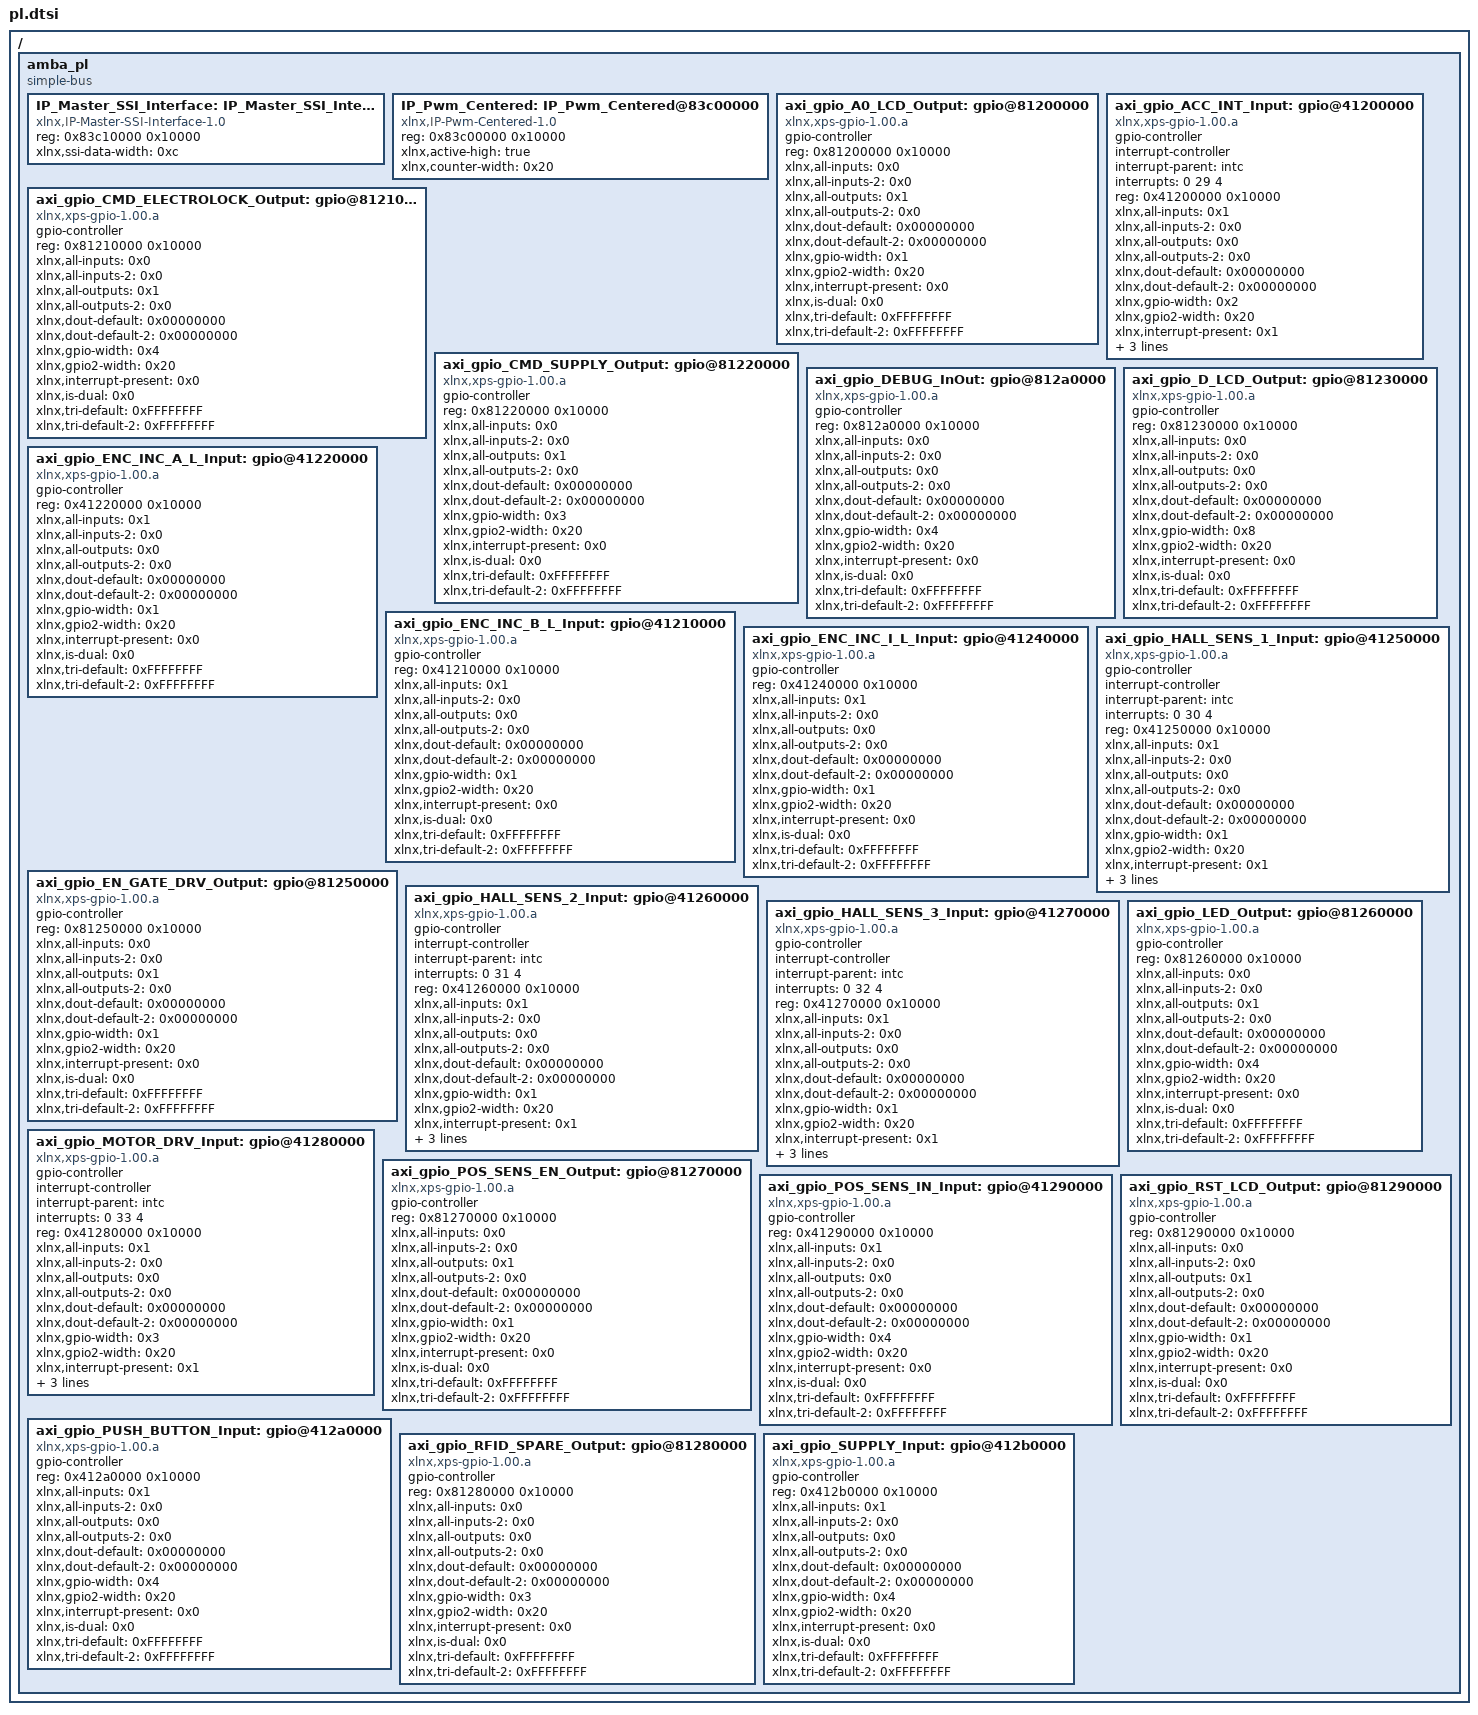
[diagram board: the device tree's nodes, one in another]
/*
 * CAUTION: This file is automatically generated by Xilinx.
 * Version:  
 * Today is: Fri May 19 15:57:43 2017
*/


/ {
	amba_pl: amba_pl {
		#address-cells = <1>;
		#size-cells = <1>;
		compatible = "simple-bus";
		ranges ;
		IP_Master_SSI_Interface: IP_Master_SSI_Interface@83c10000 {
			compatible = "xlnx,IP-Master-SSI-Interface-1.0";
			reg = <0x83c10000 0x10000>;
			xlnx,ssi-data-width = <0xc>;
		};
		IP_Pwm_Centered: IP_Pwm_Centered@83c00000 {
			compatible = "xlnx,IP-Pwm-Centered-1.0";
			reg = <0x83c00000 0x10000>;
			xlnx,active-high = "true";
			xlnx,counter-width = <0x20>;
		};
		axi_gpio_A0_LCD_Output: gpio@81200000 {
			#gpio-cells = <2>;
			compatible = "xlnx,xps-gpio-1.00.a";
			gpio-controller ;
			reg = <0x81200000 0x10000>;
			xlnx,all-inputs = <0x0>;
			xlnx,all-inputs-2 = <0x0>;
			xlnx,all-outputs = <0x1>;
			xlnx,all-outputs-2 = <0x0>;
			xlnx,dout-default = <0x00000000>;
			xlnx,dout-default-2 = <0x00000000>;
			xlnx,gpio-width = <0x1>;
			xlnx,gpio2-width = <0x20>;
			xlnx,interrupt-present = <0x0>;
			xlnx,is-dual = <0x0>;
			xlnx,tri-default = <0xFFFFFFFF>;
			xlnx,tri-default-2 = <0xFFFFFFFF>;
		};
		axi_gpio_ACC_INT_Input: gpio@41200000 {
			#gpio-cells = <2>;
			#interrupt-cells = <2>;
			compatible = "xlnx,xps-gpio-1.00.a";
			gpio-controller ;
			interrupt-controller ;
			interrupt-parent = <&intc>;
			interrupts = <0 29 4>;
			reg = <0x41200000 0x10000>;
			xlnx,all-inputs = <0x1>;
			xlnx,all-inputs-2 = <0x0>;
			xlnx,all-outputs = <0x0>;
			xlnx,all-outputs-2 = <0x0>;
			xlnx,dout-default = <0x00000000>;
			xlnx,dout-default-2 = <0x00000000>;
			xlnx,gpio-width = <0x2>;
			xlnx,gpio2-width = <0x20>;
			xlnx,interrupt-present = <0x1>;
			xlnx,is-dual = <0x0>;
			xlnx,tri-default = <0xFFFFFFFF>;
			xlnx,tri-default-2 = <0xFFFFFFFF>;
		};
		axi_gpio_CMD_ELECTROLOCK_Output: gpio@81210000 {
			#gpio-cells = <2>;
			compatible = "xlnx,xps-gpio-1.00.a";
			gpio-controller ;
			reg = <0x81210000 0x10000>;
			xlnx,all-inputs = <0x0>;
			xlnx,all-inputs-2 = <0x0>;
			xlnx,all-outputs = <0x1>;
			xlnx,all-outputs-2 = <0x0>;
			xlnx,dout-default = <0x00000000>;
			xlnx,dout-default-2 = <0x00000000>;
			xlnx,gpio-width = <0x4>;
			xlnx,gpio2-width = <0x20>;
			xlnx,interrupt-present = <0x0>;
			xlnx,is-dual = <0x0>;
			xlnx,tri-default = <0xFFFFFFFF>;
			xlnx,tri-default-2 = <0xFFFFFFFF>;
		};
		axi_gpio_CMD_SUPPLY_Output: gpio@81220000 {
			#gpio-cells = <2>;
			compatible = "xlnx,xps-gpio-1.00.a";
			gpio-controller ;
			reg = <0x81220000 0x10000>;
			xlnx,all-inputs = <0x0>;
			xlnx,all-inputs-2 = <0x0>;
			xlnx,all-outputs = <0x1>;
			xlnx,all-outputs-2 = <0x0>;
			xlnx,dout-default = <0x00000000>;
			xlnx,dout-default-2 = <0x00000000>;
			xlnx,gpio-width = <0x3>;
			xlnx,gpio2-width = <0x20>;
			xlnx,interrupt-present = <0x0>;
			xlnx,is-dual = <0x0>;
			xlnx,tri-default = <0xFFFFFFFF>;
			xlnx,tri-default-2 = <0xFFFFFFFF>;
		};
		axi_gpio_DEBUG_InOut: gpio@812a0000 {
			#gpio-cells = <2>;
			compatible = "xlnx,xps-gpio-1.00.a";
			gpio-controller ;
			reg = <0x812a0000 0x10000>;
			xlnx,all-inputs = <0x0>;
			xlnx,all-inputs-2 = <0x0>;
			xlnx,all-outputs = <0x0>;
			xlnx,all-outputs-2 = <0x0>;
			xlnx,dout-default = <0x00000000>;
			xlnx,dout-default-2 = <0x00000000>;
			xlnx,gpio-width = <0x4>;
			xlnx,gpio2-width = <0x20>;
			xlnx,interrupt-present = <0x0>;
			xlnx,is-dual = <0x0>;
			xlnx,tri-default = <0xFFFFFFFF>;
			xlnx,tri-default-2 = <0xFFFFFFFF>;
		};
		axi_gpio_D_LCD_Output: gpio@81230000 {
			#gpio-cells = <2>;
			compatible = "xlnx,xps-gpio-1.00.a";
			gpio-controller ;
			reg = <0x81230000 0x10000>;
			xlnx,all-inputs = <0x0>;
			xlnx,all-inputs-2 = <0x0>;
			xlnx,all-outputs = <0x0>;
			xlnx,all-outputs-2 = <0x0>;
			xlnx,dout-default = <0x00000000>;
			xlnx,dout-default-2 = <0x00000000>;
			xlnx,gpio-width = <0x8>;
			xlnx,gpio2-width = <0x20>;
			xlnx,interrupt-present = <0x0>;
			xlnx,is-dual = <0x0>;
			xlnx,tri-default = <0xFFFFFFFF>;
			xlnx,tri-default-2 = <0xFFFFFFFF>;
		};
		axi_gpio_ENC_INC_A_L_Input: gpio@41220000 {
			#gpio-cells = <2>;
			compatible = "xlnx,xps-gpio-1.00.a";
			gpio-controller ;
			reg = <0x41220000 0x10000>;
			xlnx,all-inputs = <0x1>;
			xlnx,all-inputs-2 = <0x0>;
			xlnx,all-outputs = <0x0>;
			xlnx,all-outputs-2 = <0x0>;
			xlnx,dout-default = <0x00000000>;
			xlnx,dout-default-2 = <0x00000000>;
			xlnx,gpio-width = <0x1>;
			xlnx,gpio2-width = <0x20>;
			xlnx,interrupt-present = <0x0>;
			xlnx,is-dual = <0x0>;
			xlnx,tri-default = <0xFFFFFFFF>;
			xlnx,tri-default-2 = <0xFFFFFFFF>;
		};
		axi_gpio_ENC_INC_B_L_Input: gpio@41210000 {
			#gpio-cells = <2>;
			compatible = "xlnx,xps-gpio-1.00.a";
			gpio-controller ;
			reg = <0x41210000 0x10000>;
			xlnx,all-inputs = <0x1>;
			xlnx,all-inputs-2 = <0x0>;
			xlnx,all-outputs = <0x0>;
			xlnx,all-outputs-2 = <0x0>;
			xlnx,dout-default = <0x00000000>;
			xlnx,dout-default-2 = <0x00000000>;
			xlnx,gpio-width = <0x1>;
			xlnx,gpio2-width = <0x20>;
			xlnx,interrupt-present = <0x0>;
			xlnx,is-dual = <0x0>;
			xlnx,tri-default = <0xFFFFFFFF>;
			xlnx,tri-default-2 = <0xFFFFFFFF>;
		};
		axi_gpio_ENC_INC_I_L_Input: gpio@41240000 {
			#gpio-cells = <2>;
			compatible = "xlnx,xps-gpio-1.00.a";
			gpio-controller ;
			reg = <0x41240000 0x10000>;
			xlnx,all-inputs = <0x1>;
			xlnx,all-inputs-2 = <0x0>;
			xlnx,all-outputs = <0x0>;
			xlnx,all-outputs-2 = <0x0>;
			xlnx,dout-default = <0x00000000>;
			xlnx,dout-default-2 = <0x00000000>;
			xlnx,gpio-width = <0x1>;
			xlnx,gpio2-width = <0x20>;
			xlnx,interrupt-present = <0x0>;
			xlnx,is-dual = <0x0>;
			xlnx,tri-default = <0xFFFFFFFF>;
			xlnx,tri-default-2 = <0xFFFFFFFF>;
		};
		axi_gpio_EN_GATE_DRV_Output: gpio@81250000 {
			#gpio-cells = <2>;
			compatible = "xlnx,xps-gpio-1.00.a";
			gpio-controller ;
			reg = <0x81250000 0x10000>;
			xlnx,all-inputs = <0x0>;
			xlnx,all-inputs-2 = <0x0>;
			xlnx,all-outputs = <0x1>;
			xlnx,all-outputs-2 = <0x0>;
			xlnx,dout-default = <0x00000000>;
			xlnx,dout-default-2 = <0x00000000>;
			xlnx,gpio-width = <0x1>;
			xlnx,gpio2-width = <0x20>;
			xlnx,interrupt-present = <0x0>;
			xlnx,is-dual = <0x0>;
			xlnx,tri-default = <0xFFFFFFFF>;
			xlnx,tri-default-2 = <0xFFFFFFFF>;
		};
		axi_gpio_HALL_SENS_1_Input: gpio@41250000 {
			#gpio-cells = <2>;
			#interrupt-cells = <2>;
			compatible = "xlnx,xps-gpio-1.00.a";
			gpio-controller ;
			interrupt-controller ;
			interrupt-parent = <&intc>;
			interrupts = <0 30 4>;
			reg = <0x41250000 0x10000>;
			xlnx,all-inputs = <0x1>;
			xlnx,all-inputs-2 = <0x0>;
			xlnx,all-outputs = <0x0>;
			xlnx,all-outputs-2 = <0x0>;
			xlnx,dout-default = <0x00000000>;
			xlnx,dout-default-2 = <0x00000000>;
			xlnx,gpio-width = <0x1>;
			xlnx,gpio2-width = <0x20>;
			xlnx,interrupt-present = <0x1>;
			xlnx,is-dual = <0x0>;
			xlnx,tri-default = <0xFFFFFFFF>;
			xlnx,tri-default-2 = <0xFFFFFFFF>;
		};
		axi_gpio_HALL_SENS_2_Input: gpio@41260000 {
			#gpio-cells = <2>;
			#interrupt-cells = <2>;
			compatible = "xlnx,xps-gpio-1.00.a";
			gpio-controller ;
			interrupt-controller ;
			interrupt-parent = <&intc>;
			interrupts = <0 31 4>;
			reg = <0x41260000 0x10000>;
			xlnx,all-inputs = <0x1>;
			xlnx,all-inputs-2 = <0x0>;
			xlnx,all-outputs = <0x0>;
			xlnx,all-outputs-2 = <0x0>;
			xlnx,dout-default = <0x00000000>;
			xlnx,dout-default-2 = <0x00000000>;
			xlnx,gpio-width = <0x1>;
			xlnx,gpio2-width = <0x20>;
			xlnx,interrupt-present = <0x1>;
			xlnx,is-dual = <0x0>;
			xlnx,tri-default = <0xFFFFFFFF>;
			xlnx,tri-default-2 = <0xFFFFFFFF>;
		};
		axi_gpio_HALL_SENS_3_Input: gpio@41270000 {
			#gpio-cells = <2>;
			#interrupt-cells = <2>;
			compatible = "xlnx,xps-gpio-1.00.a";
			gpio-controller ;
			interrupt-controller ;
			interrupt-parent = <&intc>;
			interrupts = <0 32 4>;
			reg = <0x41270000 0x10000>;
			xlnx,all-inputs = <0x1>;
			xlnx,all-inputs-2 = <0x0>;
			xlnx,all-outputs = <0x0>;
			xlnx,all-outputs-2 = <0x0>;
			xlnx,dout-default = <0x00000000>;
			xlnx,dout-default-2 = <0x00000000>;
			xlnx,gpio-width = <0x1>;
			xlnx,gpio2-width = <0x20>;
			xlnx,interrupt-present = <0x1>;
			xlnx,is-dual = <0x0>;
			xlnx,tri-default = <0xFFFFFFFF>;
			xlnx,tri-default-2 = <0xFFFFFFFF>;
		};
		axi_gpio_LED_Output: gpio@81260000 {
			#gpio-cells = <2>;
			compatible = "xlnx,xps-gpio-1.00.a";
			gpio-controller ;
			reg = <0x81260000 0x10000>;
			xlnx,all-inputs = <0x0>;
			xlnx,all-inputs-2 = <0x0>;
			xlnx,all-outputs = <0x1>;
			xlnx,all-outputs-2 = <0x0>;
			xlnx,dout-default = <0x00000000>;
			xlnx,dout-default-2 = <0x00000000>;
			xlnx,gpio-width = <0x4>;
			xlnx,gpio2-width = <0x20>;
			xlnx,interrupt-present = <0x0>;
			xlnx,is-dual = <0x0>;
			xlnx,tri-default = <0xFFFFFFFF>;
			xlnx,tri-default-2 = <0xFFFFFFFF>;
		};
		axi_gpio_MOTOR_DRV_Input: gpio@41280000 {
			#gpio-cells = <2>;
			#interrupt-cells = <2>;
			compatible = "xlnx,xps-gpio-1.00.a";
			gpio-controller ;
			interrupt-controller ;
			interrupt-parent = <&intc>;
			interrupts = <0 33 4>;
			reg = <0x41280000 0x10000>;
			xlnx,all-inputs = <0x1>;
			xlnx,all-inputs-2 = <0x0>;
			xlnx,all-outputs = <0x0>;
			xlnx,all-outputs-2 = <0x0>;
			xlnx,dout-default = <0x00000000>;
			xlnx,dout-default-2 = <0x00000000>;
			xlnx,gpio-width = <0x3>;
			xlnx,gpio2-width = <0x20>;
			xlnx,interrupt-present = <0x1>;
			xlnx,is-dual = <0x0>;
			xlnx,tri-default = <0xFFFFFFFF>;
			xlnx,tri-default-2 = <0xFFFFFFFF>;
		};
		axi_gpio_POS_SENS_EN_Output: gpio@81270000 {
			#gpio-cells = <2>;
			compatible = "xlnx,xps-gpio-1.00.a";
			gpio-controller ;
			reg = <0x81270000 0x10000>;
			xlnx,all-inputs = <0x0>;
			xlnx,all-inputs-2 = <0x0>;
			xlnx,all-outputs = <0x1>;
			xlnx,all-outputs-2 = <0x0>;
			xlnx,dout-default = <0x00000000>;
			xlnx,dout-default-2 = <0x00000000>;
			xlnx,gpio-width = <0x1>;
			xlnx,gpio2-width = <0x20>;
			xlnx,interrupt-present = <0x0>;
			xlnx,is-dual = <0x0>;
			xlnx,tri-default = <0xFFFFFFFF>;
			xlnx,tri-default-2 = <0xFFFFFFFF>;
		};
		axi_gpio_POS_SENS_IN_Input: gpio@41290000 {
			#gpio-cells = <2>;
			compatible = "xlnx,xps-gpio-1.00.a";
			gpio-controller ;
			reg = <0x41290000 0x10000>;
			xlnx,all-inputs = <0x1>;
			xlnx,all-inputs-2 = <0x0>;
			xlnx,all-outputs = <0x0>;
			xlnx,all-outputs-2 = <0x0>;
			xlnx,dout-default = <0x00000000>;
			xlnx,dout-default-2 = <0x00000000>;
			xlnx,gpio-width = <0x4>;
			xlnx,gpio2-width = <0x20>;
			xlnx,interrupt-present = <0x0>;
			xlnx,is-dual = <0x0>;
			xlnx,tri-default = <0xFFFFFFFF>;
			xlnx,tri-default-2 = <0xFFFFFFFF>;
		};
		axi_gpio_PUSH_BUTTON_Input: gpio@412a0000 {
			#gpio-cells = <2>;
			compatible = "xlnx,xps-gpio-1.00.a";
			gpio-controller ;
			reg = <0x412a0000 0x10000>;
			xlnx,all-inputs = <0x1>;
			xlnx,all-inputs-2 = <0x0>;
			xlnx,all-outputs = <0x0>;
			xlnx,all-outputs-2 = <0x0>;
			xlnx,dout-default = <0x00000000>;
			xlnx,dout-default-2 = <0x00000000>;
			xlnx,gpio-width = <0x4>;
			xlnx,gpio2-width = <0x20>;
			xlnx,interrupt-present = <0x0>;
			xlnx,is-dual = <0x0>;
			xlnx,tri-default = <0xFFFFFFFF>;
			xlnx,tri-default-2 = <0xFFFFFFFF>;
		};
		axi_gpio_RFID_SPARE_Output: gpio@81280000 {
			#gpio-cells = <2>;
			compatible = "xlnx,xps-gpio-1.00.a";
			gpio-controller ;
			reg = <0x81280000 0x10000>;
			xlnx,all-inputs = <0x0>;
			xlnx,all-inputs-2 = <0x0>;
			xlnx,all-outputs = <0x0>;
			xlnx,all-outputs-2 = <0x0>;
			xlnx,dout-default = <0x00000000>;
			xlnx,dout-default-2 = <0x00000000>;
			xlnx,gpio-width = <0x3>;
			xlnx,gpio2-width = <0x20>;
			xlnx,interrupt-present = <0x0>;
			xlnx,is-dual = <0x0>;
			xlnx,tri-default = <0xFFFFFFFF>;
			xlnx,tri-default-2 = <0xFFFFFFFF>;
		};
		axi_gpio_RST_LCD_Output: gpio@81290000 {
			#gpio-cells = <2>;
			compatible = "xlnx,xps-gpio-1.00.a";
			gpio-controller ;
			reg = <0x81290000 0x10000>;
			xlnx,all-inputs = <0x0>;
			xlnx,all-inputs-2 = <0x0>;
			xlnx,all-outputs = <0x1>;
			xlnx,all-outputs-2 = <0x0>;
			xlnx,dout-default = <0x00000000>;
			xlnx,dout-default-2 = <0x00000000>;
			xlnx,gpio-width = <0x1>;
			xlnx,gpio2-width = <0x20>;
			xlnx,interrupt-present = <0x0>;
			xlnx,is-dual = <0x0>;
			xlnx,tri-default = <0xFFFFFFFF>;
			xlnx,tri-default-2 = <0xFFFFFFFF>;
		};
		axi_gpio_SUPPLY_Input: gpio@412b0000 {
			#gpio-cells = <2>;
			compatible = "xlnx,xps-gpio-1.00.a";
			gpio-controller ;
			reg = <0x412b0000 0x10000>;
			xlnx,all-inputs = <0x1>;
			xlnx,all-inputs-2 = <0x0>;
			xlnx,all-outputs = <0x0>;
			xlnx,all-outputs-2 = <0x0>;
			xlnx,dout-default = <0x00000000>;
			xlnx,dout-default-2 = <0x00000000>;
			xlnx,gpio-width = <0x4>;
			xlnx,gpio2-width = <0x20>;
			xlnx,interrupt-present = <0x0>;
			xlnx,is-dual = <0x0>;
			xlnx,tri-default = <0xFFFFFFFF>;
			xlnx,tri-default-2 = <0xFFFFFFFF>;
		};
	};
};
